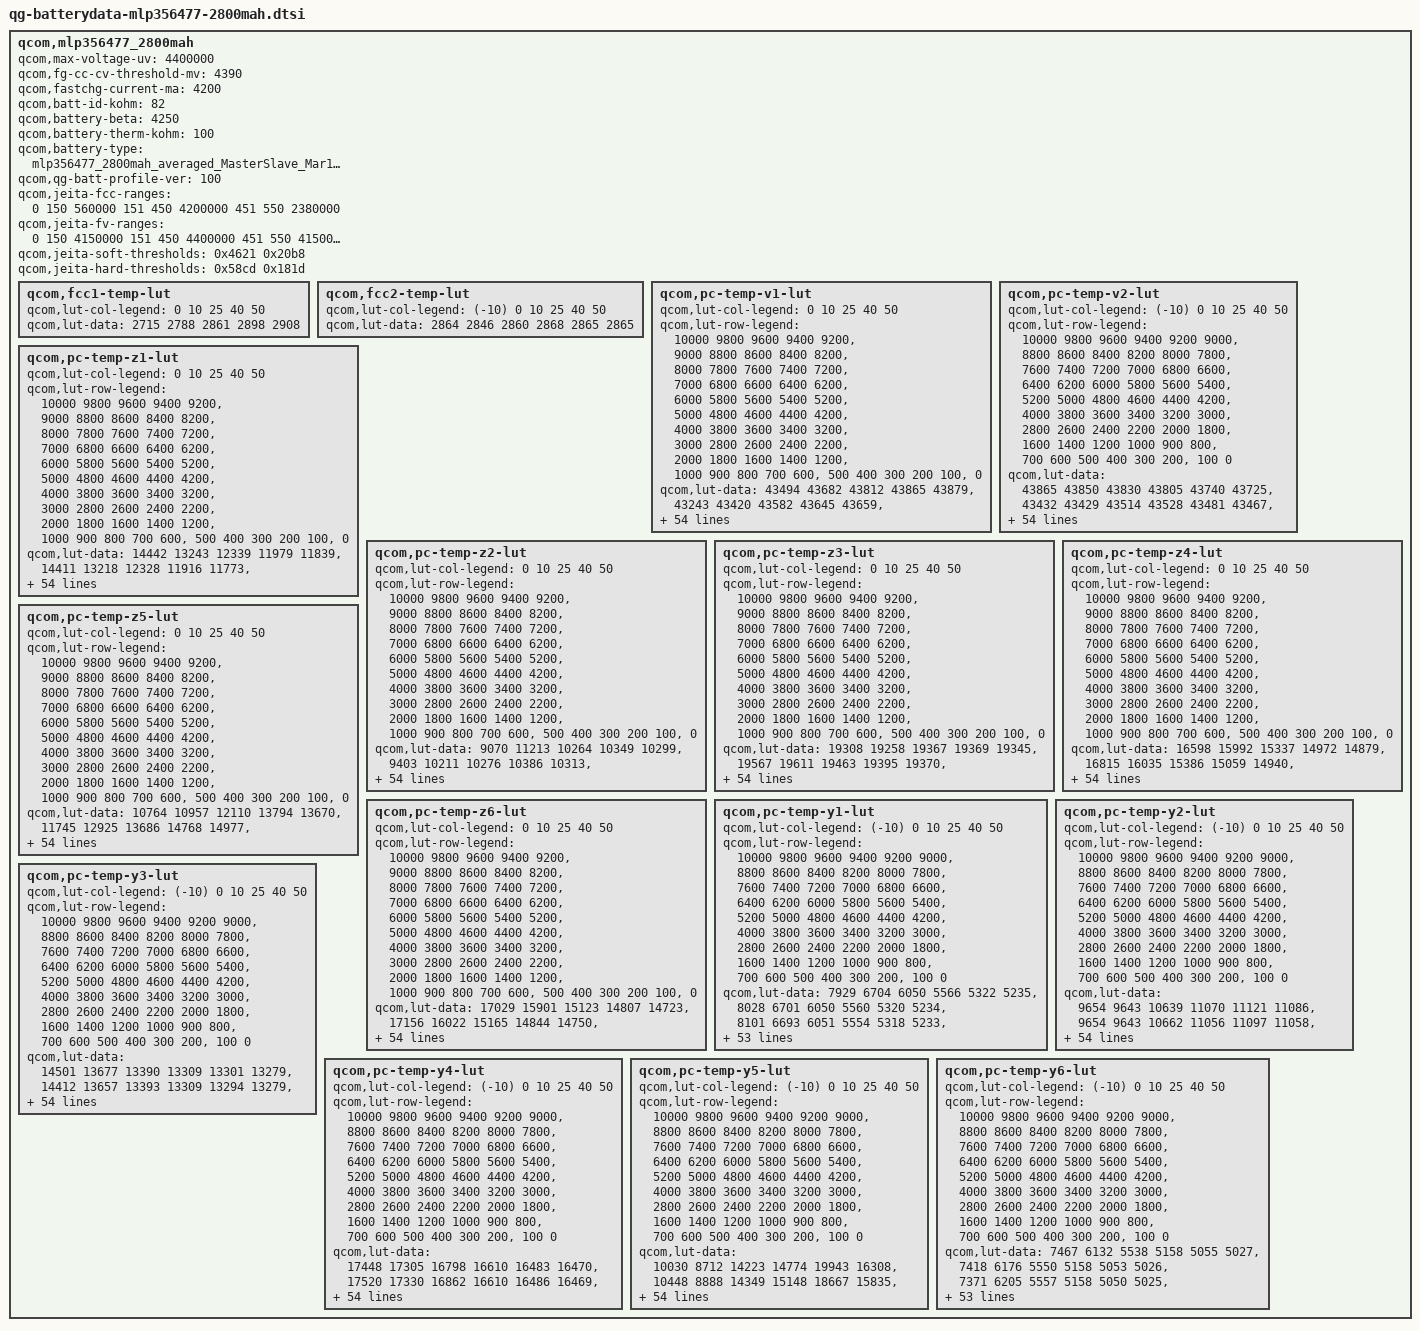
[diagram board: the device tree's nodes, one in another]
/* Copyright (c) 2018, The Linux Foundation. All rights reserved.
 *
 * This program is free software; you can redistribute it and/or modify
 * it under the terms of the GNU General Public License version 2 and
 * only version 2 as published by the Free Software Foundation.
 *
 * This program is distributed in the hope that it will be useful,
 * but WITHOUT ANY WARRANTY; without even the implied warranty of
 * MERCHANTABILITY or FITNESS FOR A PARTICULAR PURPOSE.  See the
 * GNU General Public License for more details.
 */

qcom,mlp356477_2800mah {
	/* mlp356477_2800mah_averaged_MasterSlave_Mar13th2018 */
	qcom,max-voltage-uv = <4400000>;
	qcom,fg-cc-cv-threshold-mv = <4390>;
	qcom,fastchg-current-ma = <4200>;
	qcom,batt-id-kohm = <82>;
	qcom,battery-beta = <4250>;
	qcom,battery-therm-kohm = <100>;
	qcom,battery-type =
		"mlp356477_2800mah_averaged_MasterSlave_Mar13th2018";
	qcom,qg-batt-profile-ver = <100>;

	qcom,jeita-fcc-ranges = <0   150   560000
				 151 450  4200000
				 451 550  2380000>;
	qcom,jeita-fv-ranges =  <0   150  4150000
				 151 450  4400000
				 451 550  4150000>;

	/* COOL = 15 DegC, WARM = 45 DegC */
	qcom,jeita-soft-thresholds = <0x4621 0x20b8>;
	/* COLD = 0 DegC, HOT = 55 DegC */
	qcom,jeita-hard-thresholds = <0x58cd 0x181d>;

	qcom,fcc1-temp-lut {
		qcom,lut-col-legend = <0 10 25 40 50>;
		qcom,lut-data = <2715 2788 2861 2898 2908>;
	};

	qcom,fcc2-temp-lut {
		qcom,lut-col-legend = <(-10) 0 10 25 40 50>;
		qcom,lut-data = <2864 2846 2860 2868 2865 2865>;
	};

	qcom,pc-temp-v1-lut {
		qcom,lut-col-legend = <0 10 25 40 50>;
		qcom,lut-row-legend = <10000 9800 9600 9400 9200>,
			<9000 8800 8600 8400 8200>,
			<8000 7800 7600 7400 7200>,
			<7000 6800 6600 6400 6200>,
			<6000 5800 5600 5400 5200>,
			<5000 4800 4600 4400 4200>,
			<4000 3800 3600 3400 3200>,
			<3000 2800 2600 2400 2200>,
			<2000 1800 1600 1400 1200>,
			<1000 900 800 700 600>,
			<500 400 300 200 100>,
			<0>;
		qcom,lut-data = <43494 43682 43812 43865 43879>,
			<43243 43420 43582 43645 43659>,
			<42984 43174 43350 43418 43434>,
			<42737 42940 43115 43191 43208>,
			<42506 42710 42878 42958 42978>,
			<42287 42479 42641 42722 42746>,
			<42087 42250 42407 42489 42514>,
			<41903 42027 42175 42255 42281>,
			<41709 41807 41948 42023 42050>,
			<41489 41592 41723 41794 41822>,
			<41265 41381 41502 41568 41596>,
			<41069 41176 41286 41348 41374>,
			<40898 40982 41074 41131 41155>,
			<40720 40799 40871 40921 40942>,
			<40501 40613 40673 40716 40735>,
			<40269 40405 40482 40518 40534>,
			<40088 40193 40295 40329 40343>,
			<39955 40022 40116 40148 40162>,
			<39834 39894 39952 39975 39988>,
			<39708 39765 39807 39818 39827>,
			<39583 39577 39645 39659 39667>,
			<39447 39345 39420 39461 39475>,
			<39277 39148 39173 39221 39239>,
			<39089 38991 38991 39014 39028>,
			<38930 38860 38851 38860 38868>,
			<38794 38758 38733 38728 38732>,
			<38683 38676 38628 38611 38612>,
			<38607 38602 38535 38507 38505>,
			<38548 38529 38451 38414 38409>,
			<38501 38462 38373 38327 38317>,
			<38466 38407 38305 38251 38234>,
			<38437 38360 38245 38182 38160>,
			<38405 38317 38193 38121 38092>,
			<38366 38277 38147 38067 38030>,
			<38329 38240 38109 38022 37980>,
			<38300 38203 38069 37977 37929>,
			<38273 38170 38027 37921 37863>,
			<38236 38130 37980 37857 37784>,
			<38162 38057 37912 37781 37700>,
			<38062 37946 37816 37690 37609>,
			<37947 37830 37704 37585 37507>,
			<37801 37713 37578 37463 37382>,
			<37644 37575 37436 37322 37239>,
			<37473 37394 37270 37162 37082>,
			<37320 37251 37129 37032 36959>,
			<37220 37161 37058 36960 36899>,
			<37185 37129 37033 36942 36880>,
			<37156 37103 37014 36927 36865>,
			<37120 37070 36988 36902 36835>,
			<37014 36957 36885 36755 36652>,
			<36682 36593 36544 36398 36287>,
			<36204 36109 36077 35921 35807>,
			<35597 35486 35476 35307 35181>,
			<34771 34630 34656 34460 34321>,
			<33460 33262 33379 33128 32955>,
			<30000 30000 30000 30000 30000>;
	};

	qcom,pc-temp-v2-lut {
		qcom,lut-col-legend = <(-10) 0 10 25 40 50>;
		qcom,lut-row-legend = <10000 9800 9600 9400 9200 9000>,
			<8800 8600 8400 8200 8000 7800>,
			<7600 7400 7200 7000 6800 6600>,
			<6400 6200 6000 5800 5600 5400>,
			<5200 5000 4800 4600 4400 4200>,
			<4000 3800 3600 3400 3200 3000>,
			<2800 2600 2400 2200 2000 1800>,
			<1600 1400 1200 1000 900 800>,
			<700 600 500 400 300 200>,
			<100 0>;
		qcom,lut-data = <43865 43850 43830 43805 43740 43725>,
			<43432 43429 43514 43528 43481 43467>,
			<43037 43064 43219 43264 43228 43216>,
			<42685 42767 42948 43012 42983 42973>,
			<42369 42526 42700 42773 42744 42738>,
			<42075 42296 42458 42537 42509 42505>,
			<41776 42059 42213 42303 42277 42272>,
			<41517 41822 41972 42071 42047 42041>,
			<41353 41571 41739 41843 41820 41814>,
			<41239 41298 41515 41619 41595 41589>,
			<41095 41069 41297 41398 41374 41368>,
			<40895 40928 41088 41181 41158 41151>,
			<40650 40808 40884 40967 40946 40938>,
			<40329 40611 40677 40763 40742 40734>,
			<39941 40284 40461 40566 40541 40534>,
			<39654 39989 40259 40373 40348 40342>,
			<39456 39811 40087 40180 40164 40158>,
			<39278 39662 39920 39993 39985 39980>,
			<39086 39459 39722 39821 39814 39808>,
			<38900 39184 39492 39664 39651 39646>,
			<38740 38924 39264 39483 39469 39466>,
			<38598 38721 39048 39237 39230 39230>,
			<38480 38546 38846 38982 38986 38989>,
			<38386 38403 38678 38799 38809 38813>,
			<38308 38282 38535 38654 38669 38674>,
			<38240 38189 38406 38530 38547 38552>,
			<38182 38125 38286 38419 38438 38442>,
			<38127 38075 38179 38320 38341 38343>,
			<38076 38030 38090 38229 38250 38250>,
			<38028 37992 38012 38144 38166 38164>,
			<37978 37955 37949 38066 38089 38086>,
			<37927 37916 37900 37993 38019 38016>,
			<37875 37875 37857 37925 37953 37949>,
			<37820 37832 37817 37860 37884 37875>,
			<37763 37788 37781 37801 37812 37795>,
			<37699 37738 37740 37738 37728 37702>,
			<37630 37680 37688 37671 37625 37587>,
			<37555 37613 37625 37600 37519 37469>,
			<37475 37537 37552 37525 37430 37374>,
			<37392 37448 37465 37446 37352 37292>,
			<37308 37349 37363 37353 37263 37200>,
			<37222 37237 37238 37238 37151 37088>,
			<37133 37114 37101 37106 37022 36960>,
			<37035 36989 36957 36952 36870 36813>,
			<36935 36875 36859 36862 36807 36758>,
			<36817 36792 36792 36828 36785 36734>,
			<36752 36754 36762 36812 36769 36719>,
			<36667 36707 36710 36780 36736 36687>,
			<36541 36633 36613 36721 36656 36581>,
			<36342 36472 36411 36517 36379 36276>,
			<36024 36149 36031 36113 35946 35829>,
			<35575 35650 35485 35584 35386 35258>,
			<34953 34964 34771 34884 34643 34500>,
			<34073 34007 33739 33902 33598 33440>,
			<32647 32474 32144 32393 32025 31829>,
			<30018 28051 26513 28737 27554 26991>;
	};

	qcom,pc-temp-z1-lut {
		qcom,lut-col-legend = <0 10 25 40 50>;
		qcom,lut-row-legend = <10000 9800 9600 9400 9200>,
			<9000 8800 8600 8400 8200>,
			<8000 7800 7600 7400 7200>,
			<7000 6800 6600 6400 6200>,
			<6000 5800 5600 5400 5200>,
			<5000 4800 4600 4400 4200>,
			<4000 3800 3600 3400 3200>,
			<3000 2800 2600 2400 2200>,
			<2000 1800 1600 1400 1200>,
			<1000 900 800 700 600>,
			<500 400 300 200 100>,
			<0>;
		qcom,lut-data = <14442 13243 12339 11979 11839>,
			<14411 13218 12328 11916 11773>,
			<14392 13199 12294 11893 11756>,
			<14384 13180 12273 11879 11745>,
			<14381 13174 12263 11870 11738>,
			<14377 13179 12257 11863 11735>,
			<14369 13182 12253 11858 11731>,
			<14358 13175 12250 11851 11726>,
			<14349 13158 12248 11847 11722>,
			<14339 13146 12242 11845 11720>,
			<14332 13143 12237 11845 11719>,
			<14327 13144 12237 11844 11718>,
			<14321 13142 12238 11840 11716>,
			<14313 13135 12234 11837 11715>,
			<14306 13128 12222 11835 11714>,
			<14299 13120 12215 11834 11714>,
			<14293 13113 12211 11833 11713>,
			<14293 13111 12203 11830 11714>,
			<14297 13119 12202 11828 11715>,
			<14304 13129 12210 11831 11716>,
			<14312 13133 12215 11837 11718>,
			<14318 13130 12221 11841 11721>,
			<14319 13125 12230 11843 11726>,
			<14320 13135 12234 11846 11730>,
			<14324 13151 12236 11852 11734>,
			<14340 13158 12238 11860 11737>,
			<14358 13165 12247 11865 11741>,
			<14373 13167 12258 11870 11747>,
			<14389 13165 12260 11873 11752>,
			<14394 13167 12258 11877 11757>,
			<14373 13169 12256 11880 11760>,
			<14334 13168 12253 11886 11764>,
			<14321 13167 12247 11892 11768>,
			<14348 13170 12248 11897 11772>,
			<14378 13177 12260 11901 11778>,
			<14371 13182 12271 11905 11783>,
			<14343 13188 12277 11910 11788>,
			<14331 13194 12283 11917 11792>,
			<14346 13205 12290 11924 11797>,
			<14369 13219 12300 11931 11803>,
			<14389 13228 12307 11937 11809>,
			<14412 13237 12311 11941 11815>,
			<14410 13245 12315 11945 11820>,
			<14367 13259 12315 11949 11823>,
			<14429 13239 12311 11954 11824>,
			<14440 13243 12333 11959 11830>,
			<14452 13241 12320 11961 11828>,
			<14443 13243 12329 11964 11831>,
			<14484 13241 12332 11968 11836>,
			<14448 13263 12343 11977 11845>,
			<14473 13293 12346 11988 11856>,
			<14501 13300 12357 12000 11864>,
			<14521 13333 12374 12015 11879>,
			<14603 13373 12420 12034 11897>,
			<14603 13373 12420 12034 11897>,
			<14603 13373 12420 12034 11897>;
	};

	qcom,pc-temp-z2-lut {
		qcom,lut-col-legend = <0 10 25 40 50>;
		qcom,lut-row-legend = <10000 9800 9600 9400 9200>,
			<9000 8800 8600 8400 8200>,
			<8000 7800 7600 7400 7200>,
			<7000 6800 6600 6400 6200>,
			<6000 5800 5600 5400 5200>,
			<5000 4800 4600 4400 4200>,
			<4000 3800 3600 3400 3200>,
			<3000 2800 2600 2400 2200>,
			<2000 1800 1600 1400 1200>,
			<1000 900 800 700 600>,
			<500 400 300 200 100>,
			<0>;
		qcom,lut-data = <9070 11213 10264 10349 10299>,
			<9403 10211 10276 10386 10313>,
			<9826 10116 10342 10430 10322>,
			<9983 10114 10362 10447 10350>,
			<9978 10115 10368 10437 10342>,
			<9967 10120 10372 10407 10282>,
			<9846 10126 10371 10393 10237>,
			<9534 10132 10368 10388 10217>,
			<9372 10137 10365 10382 10206>,
			<9574 10141 10365 10378 10208>,
			<9873 10143 10365 10386 10216>,
			<9940 10145 10357 10384 10231>,
			<9908 10147 10346 10370 10273>,
			<9890 10148 10344 10357 10310>,
			<9864 10149 10352 10353 10325>,
			<9749 10147 10354 10353 10336>,
			<9714 10144 10347 10355 10342>,
			<10069 10146 10343 10360 10343>,
			<10530 10156 10344 10366 10344>,
			<10637 10166 10343 10378 10353>,
			<10631 10154 10344 10396 10363>,
			<10605 10119 10374 10405 10360>,
			<10392 10103 10415 10412 10326>,
			<10061 10118 10414 10414 10294>,
			<9958 10135 10371 10402 10266>,
			<9962 10132 10339 10387 10241>,
			<9968 10117 10335 10377 10241>,
			<9971 10107 10337 10360 10253>,
			<9975 10109 10342 10353 10270>,
			<9977 10112 10351 10373 10299>,
			<9855 10116 10359 10397 10330>,
			<9628 10123 10362 10398 10343>,
			<9563 10131 10365 10389 10349>,
			<9597 10143 10370 10392 10366>,
			<9647 10159 10379 10443 10415>,
			<9714 10166 10389 10499 10464>,
			<9809 10169 10397 10520 10486>,
			<9844 10172 10405 10533 10511>,
			<9756 10186 10432 10548 10531>,
			<9631 10212 10505 10586 10563>,
			<9541 10225 10551 10621 10587>,
			<9445 10161 10538 10637 10540>,
			<9378 10144 10527 10646 10468>,
			<9335 10322 10539 10611 10495>,
			<9269 13378 10554 10627 10491>,
			<9218 14361 10475 10629 10534>,
			<9220 14794 10469 10642 10588>,
			<9212 15070 10496 10651 10586>,
			<9188 13785 10469 10739 10647>,
			<9170 13219 10622 10694 10458>,
			<9151 12652 10655 10557 10325>,
			<9135 12236 10610 10495 10272>,
			<9116 11644 10496 10432 10195>,
			<9081 11027 10456 10300 10139>,
			<9081 11027 10456 10300 10139>,
			<9081 11027 10456 10300 10139>;
	};

	qcom,pc-temp-z3-lut {
		qcom,lut-col-legend = <0 10 25 40 50>;
		qcom,lut-row-legend = <10000 9800 9600 9400 9200>,
			<9000 8800 8600 8400 8200>,
			<8000 7800 7600 7400 7200>,
			<7000 6800 6600 6400 6200>,
			<6000 5800 5600 5400 5200>,
			<5000 4800 4600 4400 4200>,
			<4000 3800 3600 3400 3200>,
			<3000 2800 2600 2400 2200>,
			<2000 1800 1600 1400 1200>,
			<1000 900 800 700 600>,
			<500 400 300 200 100>,
			<0>;
		qcom,lut-data = <19308 19258 19367 19369 19345>,
			<19567 19611 19463 19395 19370>,
			<19850 19705 19512 19411 19381>,
			<19967 19740 19520 19416 19385>,
			<19987 19749 19515 19414 19384>,
			<19996 19735 19507 19405 19379>,
			<19860 19713 19499 19400 19373>,
			<19484 19698 19492 19395 19369>,
			<19288 19687 19483 19391 19365>,
			<19508 19679 19473 19388 19362>,
			<19829 19673 19467 19382 19358>,
			<19858 19667 19463 19378 19357>,
			<19678 19660 19461 19372 19355>,
			<19567 19648 19461 19369 19353>,
			<19627 19641 19463 19369 19353>,
			<19647 19646 19465 19368 19355>,
			<19577 19654 19458 19367 19355>,
			<19415 19653 19447 19366 19345>,
			<19268 19631 19443 19365 19337>,
			<19258 19613 19443 19365 19337>,
			<19258 19623 19446 19366 19337>,
			<19260 19652 19459 19374 19342>,
			<19450 19665 19480 19393 19364>,
			<19797 19666 19494 19403 19379>,
			<19919 19667 19506 19402 19379>,
			<19924 19671 19511 19400 19378>,
			<19927 19681 19507 19400 19374>,
			<19922 19686 19499 19400 19366>,
			<19906 19684 19492 19399 19360>,
			<19891 19680 19487 19397 19359>,
			<19798 19673 19482 19393 19359>,
			<19639 19661 19476 19390 19359>,
			<19579 19650 19470 19386 19357>,
			<19566 19644 19465 19382 19355>,
			<19553 19639 19460 19380 19352>,
			<19468 19636 19457 19378 19348>,
			<19316 19630 19455 19375 19346>,
			<19261 19624 19453 19373 19344>,
			<19262 19618 19450 19371 19343>,
			<19263 19609 19443 19369 19345>,
			<19264 19576 19437 19368 19347>,
			<19267 19367 19435 19368 19350>,
			<19269 19261 19432 19367 19353>,
			<19270 19260 19421 19365 19353>,
			<19274 19257 19413 19361 19354>,
			<19278 19257 19368 19354 19332>,
			<19278 19257 19367 19346 19332>,
			<19279 19257 19362 19331 19323>,
			<19282 19257 19368 19326 19327>,
			<19284 19257 19354 19338 19350>,
			<19287 19257 19361 19346 19348>,
			<19290 19257 19368 19356 19347>,
			<19295 19257 19370 19353 19356>,
			<19308 19258 19392 19382 19373>,
			<19308 19258 19392 19382 19373>,
			<19308 19258 19392 19382 19373>;
	};

	qcom,pc-temp-z4-lut {
		qcom,lut-col-legend = <0 10 25 40 50>;
		qcom,lut-row-legend = <10000 9800 9600 9400 9200>,
			<9000 8800 8600 8400 8200>,
			<8000 7800 7600 7400 7200>,
			<7000 6800 6600 6400 6200>,
			<6000 5800 5600 5400 5200>,
			<5000 4800 4600 4400 4200>,
			<4000 3800 3600 3400 3200>,
			<3000 2800 2600 2400 2200>,
			<2000 1800 1600 1400 1200>,
			<1000 900 800 700 600>,
			<500 400 300 200 100>,
			<0>;
		qcom,lut-data = <16598 15992 15337 14972 14879>,
			<16815 16035 15386 15059 14940>,
			<16561 15923 15277 14982 14899>,
			<16283 15657 15173 14901 14842>,
			<15982 15436 15082 14879 14824>,
			<15774 15304 15020 14868 14816>,
			<15800 15207 14988 14856 14809>,
			<15941 15154 14966 14843 14802>,
			<16005 15119 14946 14830 14794>,
			<15750 15094 14928 14818 14785>,
			<15383 15076 14912 14807 14775>,
			<15316 15063 14897 14797 14766>,
			<15433 15048 14884 14788 14757>,
			<15501 15033 14874 14778 14748>,
			<15463 15025 14866 14769 14737>,
			<15509 15037 14860 14760 14725>,
			<15596 15057 14852 14751 14718>,
			<15677 15056 14841 14742 14715>,
			<15729 15002 14835 14738 14712>,
			<15708 14951 14832 14736 14709>,
			<15684 15017 14833 14735 14707>,
			<15650 15207 14923 14756 14718>,
			<15508 15302 15068 14837 14777>,
			<15298 15313 15091 14879 14814>,
			<15235 15319 15040 14870 14809>,
			<15282 15294 14989 14855 14800>,
			<15330 15200 14962 14841 14793>,
			<15320 15131 14943 14826 14787>,
			<15270 15105 14932 14814 14780>,
			<15232 15088 14926 14805 14771>,
			<15276 15076 14923 14798 14761>,
			<15373 15065 14921 14794 14754>,
			<15397 15057 14920 14791 14747>,
			<15385 15051 14919 14789 14742>,
			<15376 15043 14916 14787 14738>,
			<15430 15036 14914 14786 14736>,
			<15544 15016 14915 14794 14745>,
			<15577 14998 14918 14811 14767>,
			<15550 14991 14917 14816 14774>,
			<15520 14987 14909 14811 14768>,
			<15502 14998 14896 14803 14760>,
			<15491 15139 14873 14788 14752>,
			<15475 15211 14850 14774 14747>,
			<15445 15195 14842 14774 14750>,
			<15345 15130 14813 14764 14741>,
			<15318 15079 14802 14736 14721>,
			<15308 15066 14777 14720 14700>,
			<15301 15057 14757 14705 14684>,
			<15285 15045 14739 14698 14668>,
			<15274 15053 14775 14717 14688>,
			<15294 15076 14782 14719 14696>,
			<15311 15080 14778 14712 14701>,
			<15326 15091 14779 14719 14701>,
			<15354 15108 14768 14706 14703>,
			<15354 15108 14768 14706 14703>,
			<15354 15108 14768 14706 14703>;
	};

	qcom,pc-temp-z5-lut {
		qcom,lut-col-legend = <0 10 25 40 50>;
		qcom,lut-row-legend = <10000 9800 9600 9400 9200>,
			<9000 8800 8600 8400 8200>,
			<8000 7800 7600 7400 7200>,
			<7000 6800 6600 6400 6200>,
			<6000 5800 5600 5400 5200>,
			<5000 4800 4600 4400 4200>,
			<4000 3800 3600 3400 3200>,
			<3000 2800 2600 2400 2200>,
			<2000 1800 1600 1400 1200>,
			<1000 900 800 700 600>,
			<500 400 300 200 100>,
			<0>;
		qcom,lut-data = <10764 10957 12110 13794 13670>,
			<11745 12925 13686 14768 14977>,
			<12716 14010 14746 16056 16445>,
			<13404 14718 15521 16744 17361>,
			<13905 15321 16180 16789 17415>,
			<14200 15933 16545 16568 17166>,
			<13611 16455 16653 16420 16940>,
			<11869 16730 16710 16364 16838>,
			<10978 16895 16699 16401 16763>,
			<12521 17062 16594 16402 16659>,
			<14783 17315 16549 16292 16587>,
			<15011 17507 16656 16178 16634>,
			<13819 17490 16845 16003 16770>,
			<13134 17527 17100 15977 16943>,
			<13823 17638 17538 16159 17435>,
			<14192 17626 17786 16425 18421>,
			<13660 17482 17557 16723 18632>,
			<12194 17384 17254 17131 17493>,
			<10877 17447 17366 17305 16542>,
			<10795 17704 18253 17609 16717>,
			<10808 18910 18937 18108 17070>,
			<10857 21136 18167 17900 17037>,
			<13850 21892 16713 16569 16529>,
			<19285 19957 16394 15708 16174>,
			<21102 17736 16736 15560 16006>,
			<20977 17560 17186 15557 15832>,
			<20752 18050 17734 15845 15773>,
			<20272 18693 18431 16567 15708>,
			<19413 19705 19132 17289 15707>,
			<18772 20743 19927 17959 16182>,
			<17386 21034 20581 18611 16967>,
			<15327 21059 21018 19179 17620>,
			<14631 21034 21355 19699 18403>,
			<14512 21133 21507 20256 19056>,
			<14338 21373 21604 21000 19675>,
			<13329 21460 21643 21494 20064>,
			<11563 21322 21601 20994 19488>,
			<10927 21163 21493 19730 18023>,
			<10937 21134 21270 19156 17559>,
			<10948 21040 20651 18991 17865>,
			<10942 20318 20135 18929 18319>,
			<10912 14582 19994 18903 18925>,
			<10885 11608 19761 18788 19444>,
			<10861 11587 18126 17802 18686>,
			<10871 11314 17978 17266 18426>,
			<10857 11130 15054 17271 15914>,
			<10841 11088 15214 17078 16658>,
			<10831 11067 15184 16484 17071>,
			<10841 11046 15966 16365 19357>,
			<10877 11142 14378 15551 19427>,
			<10922 11156 14140 15626 17699>,
			<10887 11109 14272 16679 16814>,
			<10848 11069 14202 15606 17668>,
			<10790 10995 15166 19180 19716>,
			<10790 10995 15166 19180 19716>,
			<10790 10995 15166 19180 19716>;
	};

	qcom,pc-temp-z6-lut {
		qcom,lut-col-legend = <0 10 25 40 50>;
		qcom,lut-row-legend = <10000 9800 9600 9400 9200>,
			<9000 8800 8600 8400 8200>,
			<8000 7800 7600 7400 7200>,
			<7000 6800 6600 6400 6200>,
			<6000 5800 5600 5400 5200>,
			<5000 4800 4600 4400 4200>,
			<4000 3800 3600 3400 3200>,
			<3000 2800 2600 2400 2200>,
			<2000 1800 1600 1400 1200>,
			<1000 900 800 700 600>,
			<500 400 300 200 100>,
			<0>;
		qcom,lut-data = <17029 15901 15123 14807 14723>,
			<17156 16022 15165 14844 14750>,
			<17081 15990 15131 14815 14734>,
			<16977 15851 15090 14780 14711>,
			<16818 15720 15039 14766 14700>,
			<16645 15630 15000 14756 14693>,
			<16486 15560 14978 14746 14686>,
			<16331 15519 14962 14737 14680>,
			<16255 15490 14945 14728 14674>,
			<16244 15468 14929 14720 14668>,
			<16238 15452 14916 14712 14662>,
			<16217 15438 14905 14704 14656>,
			<16172 15422 14897 14697 14651>,
			<16139 15401 14891 14691 14646>,
			<16146 15390 14887 14686 14642>,
			<16166 15395 14883 14681 14638>,
			<16163 15403 14876 14677 14633>,
			<16120 15402 14866 14672 14627>,
			<16076 15372 14862 14670 14622>,
			<16063 15345 14862 14670 14621>,
			<16057 15380 14865 14671 14621>,
			<16055 15480 14915 14684 14629>,
			<16092 15533 14991 14732 14668>,
			<16168 15543 15006 14757 14692>,
			<16218 15549 14992 14753 14691>,
			<16251 15541 14976 14746 14687>,
			<16270 15511 14964 14741 14683>,
			<16266 15488 14954 14735 14676>,
			<16246 15479 14948 14730 14671>,
			<16227 15473 14944 14726 14666>,
			<16204 15467 14942 14722 14662>,
			<16176 15459 14941 14719 14659>,
			<16164 15454 14939 14716 14657>,
			<16159 15453 14938 14715 14654>,
			<16154 15453 14937 14714 14651>,
			<16145 15453 14936 14714 14649>,
			<16133 15450 14939 14717 14652>,
			<16130 15447 14943 14725 14662>,
			<16133 15449 14943 14727 14665>,
			<16139 15454 14940 14725 14664>,
			<16147 15454 14936 14723 14663>,
			<16161 15429 14929 14718 14662>,
			<16171 15417 14922 14712 14662>,
			<16178 15424 14918 14713 14664>,
			<16162 15408 14909 14708 14663>,
			<16165 15399 14883 14694 14643>,
			<16168 15398 14875 14684 14633>,
			<16172 15401 14867 14670 14622>,
			<16179 15405 14866 14665 14618>,
			<16193 15425 14881 14682 14641>,
			<16228 15451 14892 14690 14645>,
			<16262 15468 14902 14695 14650>,
			<16300 15497 14912 14700 14657>,
			<16361 15535 14930 14716 14672>,
			<16361 15535 14930 14716 14672>,
			<16361 15535 14930 14716 14672>;
	};

	qcom,pc-temp-y1-lut {
		qcom,lut-col-legend = <(-10) 0 10 25 40 50>;
		qcom,lut-row-legend = <10000 9800 9600 9400 9200 9000>,
			<8800 8600 8400 8200 8000 7800>,
			<7600 7400 7200 7000 6800 6600>,
			<6400 6200 6000 5800 5600 5400>,
			<5200 5000 4800 4600 4400 4200>,
			<4000 3800 3600 3400 3200 3000>,
			<2800 2600 2400 2200 2000 1800>,
			<1600 1400 1200 1000 900 800>,
			<700 600 500 400 300 200>,
			<100 0>;
		qcom,lut-data = <7929 6704 6050 5566 5322 5235>,
			<8028 6701 6050 5560 5320 5234>,
			<8101 6693 6051 5554 5318 5233>,
			<8151 6684 6051 5548 5316 5231>,
			<8179 6676 6052 5543 5313 5230>,
			<8186 6673 6053 5540 5311 5228>,
			<8157 6667 6054 5539 5308 5225>,
			<8120 6659 6054 5538 5305 5222>,
			<8110 6663 6055 5536 5302 5222>,
			<8104 6693 6056 5529 5299 5222>,
			<8099 6717 6055 5525 5298 5222>,
			<8120 6716 6050 5525 5297 5220>,
			<8146 6707 6044 5526 5296 5217>,
			<8147 6706 6044 5528 5295 5216>,
			<8147 6707 6049 5533 5293 5217>,
			<8146 6709 6052 5536 5291 5217>,
			<8135 6705 6053 5534 5290 5219>,
			<8119 6699 6055 5532 5288 5221>,
			<8100 6700 6057 5532 5289 5221>,
			<8079 6708 6062 5531 5290 5220>,
			<8070 6715 6065 5531 5292 5219>,
			<8070 6712 6067 5532 5294 5220>,
			<8076 6706 6071 5532 5296 5222>,
			<8117 6703 6071 5532 5297 5223>,
			<8170 6702 6070 5532 5298 5225>,
			<8167 6702 6069 5532 5299 5227>,
			<8118 6700 6068 5535 5301 5229>,
			<8084 6699 6065 5539 5305 5232>,
			<8087 6697 6062 5540 5309 5236>,
			<8100 6691 6059 5541 5311 5240>,
			<8092 6688 6059 5542 5314 5243>,
			<8059 6691 6063 5546 5317 5244>,
			<8043 6695 6069 5550 5320 5245>,
			<8027 6693 6072 5553 5324 5247>,
			<8011 6677 6077 5556 5329 5251>,
			<8021 6667 6080 5558 5333 5255>,
			<8050 6679 6081 5563 5336 5258>,
			<8082 6697 6082 5568 5339 5261>,
			<8123 6698 6085 5570 5342 5263>,
			<8148 6684 6094 5571 5348 5265>,
			<8101 6675 6101 5572 5352 5268>,
			<8041 6691 6098 5581 5353 5271>,
			<8104 6707 6096 5586 5356 5275>,
			<8088 6704 6102 5586 5363 5282>,
			<8048 6708 6104 5593 5368 5284>,
			<8055 6725 6098 5595 5370 5288>,
			<8059 6724 6114 5601 5370 5288>,
			<8092 6743 6089 5598 5376 5290>,
			<8157 6750 6086 5605 5374 5291>,
			<8197 6722 6104 5609 5381 5293>,
			<8269 6738 6105 5608 5384 5292>,
			<8288 6759 6112 5624 5392 5304>,
			<8380 6766 6128 5643 5400 5313>,
			<8422 6779 6149 5656 5417 5324>,
			<8422 6779 6149 5656 5417 5324>,
			<8422 6779 6149 5656 5417 5324>;
	};

	qcom,pc-temp-y2-lut {
		qcom,lut-col-legend = <(-10) 0 10 25 40 50>;
		qcom,lut-row-legend = <10000 9800 9600 9400 9200 9000>,
			<8800 8600 8400 8200 8000 7800>,
			<7600 7400 7200 7000 6800 6600>,
			<6400 6200 6000 5800 5600 5400>,
			<5200 5000 4800 4600 4400 4200>,
			<4000 3800 3600 3400 3200 3000>,
			<2800 2600 2400 2200 2000 1800>,
			<1600 1400 1200 1000 900 800>,
			<700 600 500 400 300 200>,
			<100 0>;
		qcom,lut-data = <9654 9643 10639 11070 11121 11086>,
			<9654 9643 10662 11056 11097 11058>,
			<9655 9643 10675 11037 11063 11029>,
			<9655 9871 10680 11014 11027 11001>,
			<9656 10190 10680 10988 10997 10976>,
			<9656 10325 10677 10959 10981 10958>,
			<9657 10308 10664 10918 10973 10946>,
			<9657 10282 10644 10881 10967 10935>,
			<9657 10301 10632 10875 10959 10916>,
			<9658 10440 10623 10874 10933 10882>,
			<9658 10534 10619 10874 10919 10864>,
			<9658 10489 10626 10869 10936 10874>,
			<9659 10417 10643 10861 10961 10888>,
			<9658 10413 10676 10856 10952 10885>,
			<9657 10487 10748 10851 10897 10860>,
			<9657 10553 10801 10851 10866 10840>,
			<9657 10580 10826 10885 10876 10837>,
			<9657 10597 10843 10946 10896 10845>,
			<9657 10521 10842 11018 10943 10884>,
			<9656 10042 10822 11115 11060 10984>,
			<9656 9696 10809 11159 11120 11034>,
			<9656 9682 10815 11129 11098 11013>,
			<9656 9676 10826 11091 11071 10987>,
			<9656 9675 10835 11085 11079 11009>,
			<9656 9676 10846 11088 11121 11106>,
			<9655 9676 10848 11093 11154 11162>,
			<9655 9675 10684 11108 11176 11166>,
			<9655 9671 10460 11130 11199 11168>,
			<9655 9668 10652 11152 11224 11182>,
			<9654 9665 11565 11178 11263 11214>,
			<9654 9662 12069 11192 11286 11238>,
			<9654 9660 11796 11199 11310 11257>,
			<9654 9659 11319 11203 11338 11277>,
			<9654 9657 10963 11202 11344 11307>,
			<9654 9656 10643 11198 11320 11345>,
			<9654 9655 10423 11189 11299 11359>,
			<9653 9654 10140 11148 11294 11325>,
			<9653 9653 9828 11108 11301 11280>,
			<9653 9653 9733 11099 11301 11271>,
			<9653 9653 9707 11096 11290 11278>,
			<9653 9652 9692 11071 11287 11277>,
			<9653 9652 9681 10975 11329 11250>,
			<9653 9652 9674 10939 11356 11231>,
			<9653 9652 9668 10913 11303 11229>,
			<9653 9652 9664 10802 11253 11135>,
			<9653 9652 9663 10839 11180 11044>,
			<9653 9652 9661 10832 11146 11009>,
			<9652 9652 9660 10811 11105 10962>,
			<9652 9651 9659 10794 11061 10965>,
			<9651 9651 9658 10764 11053 10938>,
			<9650 9651 9658 10711 10981 10871>,
			<9650 9651 9656 10651 10927 10829>,
			<9649 9651 9654 10594 10851 10747>,
			<9648 9651 9654 10531 10798 10659>,
			<9648 9651 9654 10531 10798 10659>,
			<9648 9651 9654 10531 10798 10659>;
	};

	qcom,pc-temp-y3-lut {
		qcom,lut-col-legend = <(-10) 0 10 25 40 50>;
		qcom,lut-row-legend = <10000 9800 9600 9400 9200 9000>,
			<8800 8600 8400 8200 8000 7800>,
			<7600 7400 7200 7000 6800 6600>,
			<6400 6200 6000 5800 5600 5400>,
			<5200 5000 4800 4600 4400 4200>,
			<4000 3800 3600 3400 3200 3000>,
			<2800 2600 2400 2200 2000 1800>,
			<1600 1400 1200 1000 900 800>,
			<700 600 500 400 300 200>,
			<100 0>;
		qcom,lut-data = <14501 13677 13390 13309 13301 13279>,
			<14412 13657 13393 13309 13294 13279>,
			<14328 13634 13397 13311 13289 13279>,
			<14249 13612 13400 13312 13285 13279>,
			<14179 13596 13403 13314 13283 13279>,
			<14117 13590 13406 13315 13282 13279>,
			<14063 13594 13408 13315 13283 13280>,
			<14017 13600 13410 13316 13286 13281>,
			<13976 13594 13412 13317 13287 13282>,
			<13939 13548 13416 13319 13287 13282>,
			<13929 13515 13419 13321 13287 13282>,
			<13957 13513 13421 13322 13289 13282>,
			<13986 13512 13423 13323 13291 13282>,
			<13945 13509 13422 13325 13291 13283>,
			<13843 13504 13414 13328 13291 13284>,
			<13803 13497 13407 13329 13291 13286>,
			<13797 13488 13401 13328 13292 13287>,
			<13793 13478 13395 13325 13294 13288>,
			<13788 13470 13387 13324 13297 13290>,
			<13783 13465 13376 13323 13301 13294>,
			<13783 13458 13367 13322 13303 13296>,
			<13788 13428 13360 13315 13297 13290>,
			<13796 13384 13354 13306 13287 13281>,
			<13814 13362 13349 13303 13283 13278>,
			<13843 13349 13346 13300 13281 13277>,
			<13874 13344 13341 13299 13280 13277>,
			<13910 13351 13308 13299 13280 13277>,
			<13952 13369 13266 13299 13282 13277>,
			<13999 13391 13259 13298 13282 13277>,
			<14052 13422 13259 13299 13283 13277>,
			<14110 13460 13258 13299 13283 13277>,
			<14174 13503 13258 13298 13283 13277>,
			<14243 13554 13259 13298 13283 13277>,
			<14318 13615 13263 13298 13283 13277>,
			<14398 13690 13285 13299 13283 13278>,
			<14481 13777 13302 13299 13283 13278>,
			<14568 13879 13294 13296 13281 13277>,
			<14658 13996 13281 13292 13279 13276>,
			<14750 14118 13282 13292 13278 13276>,
			<14850 14247 13299 13292 13277 13277>,
			<14963 14377 13319 13293 13277 13277>,
			<15082 14502 13343 13295 13277 13278>,
			<15198 14624 13368 13298 13277 13278>,
			<15302 14737 13402 13303 13278 13276>,
			<15264 14824 13470 13304 13280 13278>,
			<15439 14801 13476 13307 13284 13280>,
			<15557 14824 13517 13316 13291 13286>,
			<15783 14890 13560 13319 13292 13287>,
			<16058 14961 13607 13332 13295 13287>,
			<16423 15021 13665 13332 13292 13286>,
			<16935 15095 13703 13333 13294 13286>,
			<17701 15215 13779 13341 13296 13289>,
			<18847 15382 13934 13350 13299 13292>,
			<20636 15571 14143 13370 13308 13299>,
			<20636 15571 14143 13370 13308 13299>,
			<20636 15571 14143 13370 13308 13299>;
	};

	qcom,pc-temp-y4-lut {
		qcom,lut-col-legend = <(-10) 0 10 25 40 50>;
		qcom,lut-row-legend = <10000 9800 9600 9400 9200 9000>,
			<8800 8600 8400 8200 8000 7800>,
			<7600 7400 7200 7000 6800 6600>,
			<6400 6200 6000 5800 5600 5400>,
			<5200 5000 4800 4600 4400 4200>,
			<4000 3800 3600 3400 3200 3000>,
			<2800 2600 2400 2200 2000 1800>,
			<1600 1400 1200 1000 900 800>,
			<700 600 500 400 300 200>,
			<100 0>;
		qcom,lut-data = <17448 17305 16798 16610 16483 16470>,
			<17520 17330 16862 16610 16486 16469>,
			<17601 17378 16934 16609 16489 16468>,
			<17679 17433 17001 16608 16491 16467>,
			<17744 17479 17051 16607 16493 16467>,
			<17783 17501 17070 16605 16493 16466>,
			<17798 17503 17059 16603 16493 16466>,
			<17813 17504 17041 16601 16492 16466>,
			<17918 17511 17030 16599 16493 16466>,
			<18180 17550 17023 16599 16497 16470>,
			<18279 17608 17020 16599 16500 16473>,
			<18148 17742 17034 16602 16502 16478>,
			<17945 17902 17062 16609 16506 16483>,
			<17736 17876 17086 16619 16512 16487>,
			<17506 17547 17110 16638 16523 16492>,
			<17399 17320 17134 16659 16535 16498>,
			<17363 17344 17161 16679 16546 16506>,
			<17328 17386 17183 16703 16560 16518>,
			<17266 17370 17170 16748 16586 16537>,
			<17193 17216 17080 16821 16630 16569>,
			<17141 17060 16974 16852 16651 16585>,
			<17100 16974 16865 16754 16602 16552>,
			<17077 16908 16761 16616 16529 16502>,
			<17070 16873 16703 16567 16502 16483>,
			<17066 16851 16662 16543 16489 16473>,
			<17066 16841 16647 16535 16485 16469>,
			<17066 16841 16681 16535 16485 16470>,
			<17067 16842 16727 16535 16487 16471>,
			<17070 16843 16732 16537 16489 16474>,
			<17074 16844 16721 16543 16497 16482>,
			<17079 16845 16716 16549 16507 16491>,
			<17088 16852 16721 16554 16521 16504>,
			<17095 16866 16730 16558 16535 16515>,
			<17099 16879 16732 16556 16540 16518>,
			<17103 16893 16714 16549 16540 16515>,
			<17111 16906 16704 16540 16534 16509>,
			<17124 16920 16735 16528 16505 16492>,
			<17134 16932 16784 16517 16477 16475>,
			<17142 16941 16805 16517 16476 16471>,
			<17149 16947 16815 16522 16479 16469>,
			<17157 16950 16818 16530 16481 16469>,
			<17167 16948 16818 16544 16482 16469>,
			<17187 16945 16817 16555 16481 16467>,
			<17208 16947 16815 16561 16471 16454>,
			<17140 16965 16826 16575 16477 16456>,
			<17176 16961 16849 16584 16493 16477>,
			<17202 16977 16893 16606 16503 16495>,
			<17281 17046 16954 16635 16528 16531>,
			<17390 17107 17025 16679 16557 16532>,
			<17524 17131 17054 16682 16515 16493>,
			<17690 17101 17038 16673 16527 16498>,
			<17978 17060 17051 16712 16548 16514>,
			<18577 17063 17124 16764 16588 16554>,
			<20156 17135 17255 16879 16727 16719>,
			<20156 17135 17255 16879 16727 16719>,
			<20156 17135 17255 16879 16727 16719>;
	};

	qcom,pc-temp-y5-lut {
		qcom,lut-col-legend = <(-10) 0 10 25 40 50>;
		qcom,lut-row-legend = <10000 9800 9600 9400 9200 9000>,
			<8800 8600 8400 8200 8000 7800>,
			<7600 7400 7200 7000 6800 6600>,
			<6400 6200 6000 5800 5600 5400>,
			<5200 5000 4800 4600 4400 4200>,
			<4000 3800 3600 3400 3200 3000>,
			<2800 2600 2400 2200 2000 1800>,
			<1600 1400 1200 1000 900 800>,
			<700 600 500 400 300 200>,
			<100 0>;
		qcom,lut-data = <10030 8712 14223 14774 19943 16308>,
			<10448 8888 14349 15148 18667 15835>,
			<10794 10562 14526 15365 17009 15457>,
			<11054 12204 14713 15466 15353 15176>,
			<11214 13579 14867 15489 14086 14997>,
			<11260 14452 14948 15472 13593 14920>,
			<11143 14948 14973 15335 13800 15003>,
			<11001 15270 14986 15151 14123 15144>,
			<11151 15028 14986 15098 14118 15087>,
			<11850 13370 14973 15056 13826 14716>,
			<12871 12246 14930 14978 13664 14315>,
			<15188 13353 14287 14743 13788 13961>,
			<17100 15163 13386 14398 13870 13634>,
			<15786 15495 13334 14078 13643 13482>,
			<12439 15197 13853 13740 13191 13549>,
			<11406 14993 14346 13497 12887 13638>,
			<11547 15443 14672 13207 12793 13546>,
			<11662 16191 15006 12923 12796 13423>,
			<11574 16138 15417 13004 13001 13548>,
			<11364 14708 15994 13654 13569 14033>,
			<11181 13284 16419 14434 14193 14440>,
			<10986 12599 16670 15491 14905 14826>,
			<10835 12068 16832 16433 15541 15160>,
			<10734 11544 16827 16644 15650 15196>,
			<10666 10962 16682 16591 15306 15346>,
			<10655 10655 16390 16622 15048 15474>,
			<10654 10648 14341 16597 15293 15494>,
			<10654 10645 11728 16540 15744 15472>,
			<10689 10665 11156 16578 15865 15229>,
			<10734 10802 11032 16695 15749 14663>,
			<10745 10946 10959 16756 15607 14352>,
			<10765 11017 10901 16831 15502 14290>,
			<10797 11076 10865 16959 15400 14311>,
			<10882 11177 11054 17363 15705 14665>,
			<10953 11367 12196 18097 16573 15740>,
			<10940 11520 13011 18310 16919 16424>,
			<10897 11584 12496 17269 16620 16376>,
			<10863 11627 11602 15914 16091 16215>,
			<10835 11630 11486 15213 15448 16327>,
			<10820 11595 11681 14700 14692 16543>,
			<10867 11570 11787 14330 14365 16550>,
			<10955 11579 11797 14105 14243 16259>,
			<11030 11596 11778 14219 14209 16346>,
			<11029 11509 11647 14611 15058 16893>,
			<11044 11331 11779 14198 14882 16382>,
			<11143 11388 11508 14156 14882 14589>,
			<11321 11488 11654 14603 16012 16142>,
			<11356 11493 11662 14001 15040 14960>,
			<11206 11613 11939 14918 15399 14828>,
			<10932 11747 12726 15439 17093 17327>,
			<10539 11665 12655 15981 17753 17255>,
			<10263 11585 12280 16288 17881 17960>,
			<9994 11459 12118 16141 17436 18200>,
			<9668 11818 11932 16090 17352 17825>,
			<9668 11818 11932 16090 17352 17825>,
			<9668 11818 11932 16090 17352 17825>;
	};

	qcom,pc-temp-y6-lut {
		qcom,lut-col-legend = <(-10) 0 10 25 40 50>;
		qcom,lut-row-legend = <10000 9800 9600 9400 9200 9000>,
			<8800 8600 8400 8200 8000 7800>,
			<7600 7400 7200 7000 6800 6600>,
			<6400 6200 6000 5800 5600 5400>,
			<5200 5000 4800 4600 4400 4200>,
			<4000 3800 3600 3400 3200 3000>,
			<2800 2600 2400 2200 2000 1800>,
			<1600 1400 1200 1000 900 800>,
			<700 600 500 400 300 200>,
			<100 0>;
		qcom,lut-data = <7467 6132 5538 5158 5055 5027>,
			<7418 6176 5550 5158 5053 5026>,
			<7371 6205 5557 5158 5050 5025>,
			<7326 6223 5561 5157 5048 5025>,
			<7283 6232 5562 5156 5046 5025>,
			<7242 6234 5562 5154 5046 5025>,
			<7194 6227 5555 5152 5046 5025>,
			<7159 6211 5540 5150 5047 5026>,
			<7167 6191 5531 5149 5047 5027>,
			<7202 6161 5522 5149 5048 5028>,
			<7216 6144 5519 5149 5049 5029>,
			<7195 6170 5520 5150 5051 5030>,
			<7155 6214 5522 5151 5053 5031>,
			<7075 6207 5523 5154 5055 5033>,
			<6953 6119 5523 5160 5058 5035>,
			<6899 6058 5522 5167 5061 5038>,
			<6884 6060 5524 5172 5065 5041>,
			<6872 6065 5527 5177 5070 5045>,
			<6853 6054 5521 5188 5079 5052>,
			<6834 5986 5487 5208 5095 5064>,
			<6828 5923 5449 5216 5102 5070>,
			<6826 5892 5413 5184 5083 5056>,
			<6825 5871 5381 5138 5056 5035>,
			<6839 5868 5365 5122 5045 5028>,
			<6867 5872 5355 5114 5040 5024>,
			<6893 5878 5349 5111 5038 5023>,
			<6923 5895 5343 5112 5039 5023>,
			<6956 5926 5339 5113 5040 5024>,
			<6991 5960 5339 5115 5042 5026>,
			<7030 5999 5342 5118 5045 5028>,
			<7074 6044 5346 5121 5048 5031>,
			<7122 6096 5354 5124 5053 5034>,
			<7175 6156 5367 5126 5057 5038>,
			<7232 6222 5383 5127 5059 5039>,
			<7293 6297 5405 5127 5060 5039>,
			<7357 6380 5430 5127 5058 5038>,
			<7425 6470 5458 5124 5049 5032>,
			<7495 6568 5491 5120 5041 5027>,
			<7567 6667 5530 5121 5040 5027>,
			<7643 6768 5579 5127 5041 5027>,
			<7727 6867 5632 5133 5042 5028>,
			<7816 6963 5689 5144 5044 5028>,
			<7908 7053 5751 5155 5044 5028>,
			<7994 7135 5817 5167 5043 5024>,
			<7959 7206 5905 5181 5046 5026>,
			<8096 7192 5921 5188 5056 5034>,
			<8195 7214 5976 5205 5063 5044>,
			<8412 7280 6034 5219 5072 5055>,
			<8678 7350 6096 5248 5083 5055>,
			<9031 7405 6155 5252 5069 5043>,
			<9521 7454 6196 5257 5074 5046>,
			<10251 7535 6282 5285 5084 5053>,
			<11352 7666 6442 5320 5100 5069>,
			<13075 7846 6646 5385 5148 5123>,
			<13075 7846 6646 5385 5148 5123>,
			<13075 7846 6646 5385 5148 5123>;
	};
};
